# jbr_MDR1986VE1T register map
Registers are 32-bit, access not given, no defined reset value unless marked. A register's access mark holds for its fields unless they carry their own. Addresses are absolute; registers are grouped by the start of their names; [hi:lo] are bit positions; {n}, {i} and the like mark numbered series; 'fields as' and 'values as' point back to an identical list.

## TIM3
0x40080000 TIM3_CNT
0x40080004 TIM3_PSG
  [15:0] PSG
0x40080008 TIM3_ARR
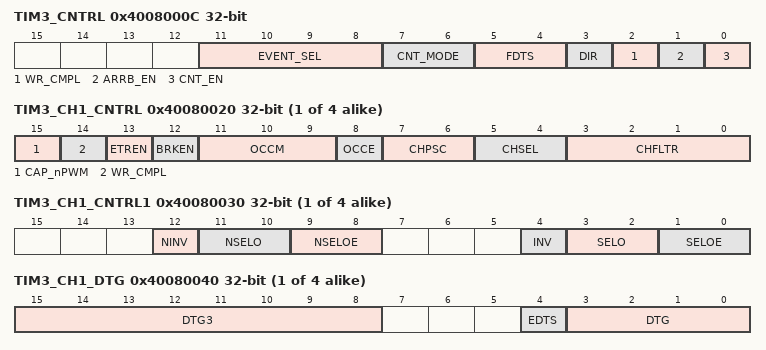
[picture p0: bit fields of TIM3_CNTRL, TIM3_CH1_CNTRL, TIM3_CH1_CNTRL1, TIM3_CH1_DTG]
0x4008000C TIM3_CNTRL
  [11:8] EVENT_SEL, [7:6] CNT_MODE, [5:4] FDTS, [3] DIR, [2] WR_CMPL, [1] ARRB_EN, [0] CNT_EN
{0x4008000C+4i} TIM3_CCR{i} (i=1..4)
  [31:0] CCR
{0x4008001C+4i} TIM3_CH{i}_CNTRL (i=1..4)
  [15] CAP_nPWM, [14] WR_CMPL, [13] ETREN, [12] BRKEN, [11:9] OCCM, [8] OCCE, [7:6] CHPSC, [5:4] CHSEL, [3:0] CHFLTR
{0x4008002C+4i} TIM3_CH{i}_CNTRL1 (i=1..4)
  [12] NINV, [11:10] NSELO, [9:8] NSELOE, [4] INV, [3:2] SELO, [1:0] SELOE
{0x4008003C+4i} TIM3_CH{i}_DTG (i=1..4)
  [15:8] DTG3, [4] EDTS, [3:0] DTG
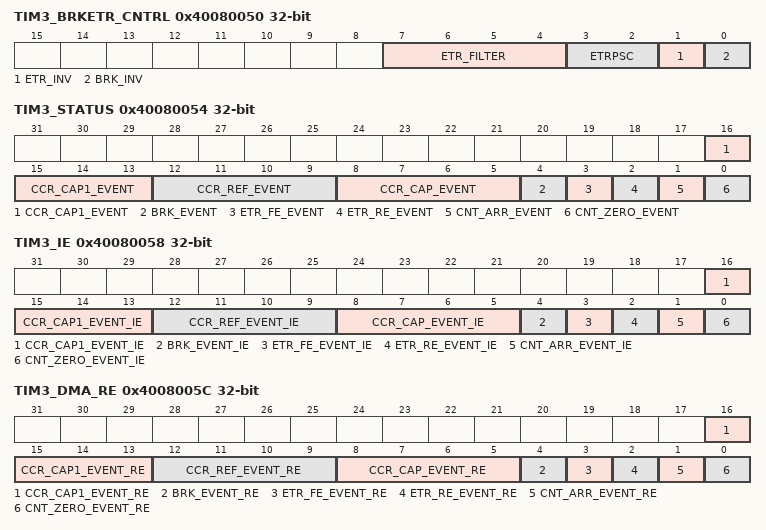
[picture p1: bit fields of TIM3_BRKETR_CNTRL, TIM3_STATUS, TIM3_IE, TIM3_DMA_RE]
0x40080050 TIM3_BRKETR_CNTRL
  [7:4] ETR_FILTER, [3:2] ETRPSC, [1] ETR_INV, [0] BRK_INV
0x40080054 TIM3_STATUS
  [16:13] CCR_CAP1_EVENT, [12:9] CCR_REF_EVENT, [8:5] CCR_CAP_EVENT, [4] BRK_EVENT, [3] ETR_FE_EVENT, [2] ETR_RE_EVENT, [1] CNT_ARR_EVENT, [0] CNT_ZERO_EVENT
0x40080058 TIM3_IE
  [16:13] CCR_CAP1_EVENT_IE, [12:9] CCR_REF_EVENT_IE, [8:5] CCR_CAP_EVENT_IE, [4] BRK_EVENT_IE, [3] ETR_FE_EVENT_IE, [2] ETR_RE_EVENT_IE, [1] CNT_ARR_EVENT_IE, [0] CNT_ZERO_EVENT_IE
0x4008005C TIM3_DMA_RE
  [16:13] CCR_CAP1_EVENT_RE, [12:9] CCR_REF_EVENT_RE, [8:5] CCR_CAP_EVENT_RE, [4] BRK_EVENT_RE, [3] ETR_FE_EVENT_RE, [2] ETR_RE_EVENT_RE, [1] CNT_ARR_EVENT_RE, [0] CNT_ZERO_EVENT_RE
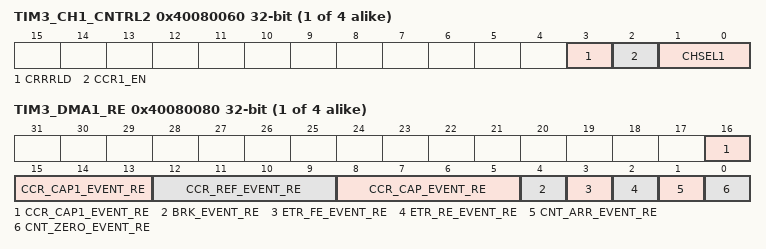
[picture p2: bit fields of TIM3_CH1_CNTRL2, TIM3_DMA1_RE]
{0x4008005C+4i} TIM3_CH{i}_CNTRL2 (i=1..4)
  [3] CRRRLD, [2] CCR1_EN, [1:0] CHSEL1
0x40080070 TIM3_CCR11
  [31:0] CCR1
0x40080074 TIM3_CCR21
  [31:0] CCR1
0x40080078 TIM3_CCR31
  [31:0] CCR1
0x4008007C TIM3_CCR41
  [31:0] CCR1
{0x4008007C+4i} TIM3_DMA{i}_RE (i=1..4)
  fields as TIM3_DMA_RE

## TIM4
0x40098000 TIM4_CNT
0x40098004 TIM4_PSG
  [15:0] PSG
0x40098008 TIM4_ARR
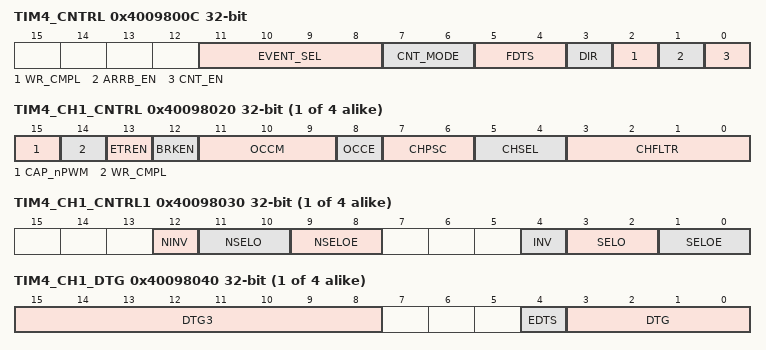
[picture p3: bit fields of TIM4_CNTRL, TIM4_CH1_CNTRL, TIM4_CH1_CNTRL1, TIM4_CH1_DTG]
0x4009800C TIM4_CNTRL
  [11:8] EVENT_SEL, [7:6] CNT_MODE, [5:4] FDTS, [3] DIR, [2] WR_CMPL, [1] ARRB_EN, [0] CNT_EN
{0x4009800C+4i} TIM4_CCR{i} (i=1..4)
  [31:0] CCR
{0x4009801C+4i} TIM4_CH{i}_CNTRL (i=1..4)
  [15] CAP_nPWM, [14] WR_CMPL, [13] ETREN, [12] BRKEN, [11:9] OCCM, [8] OCCE, [7:6] CHPSC, [5:4] CHSEL, [3:0] CHFLTR
{0x4009802C+4i} TIM4_CH{i}_CNTRL1 (i=1..4)
  [12] NINV, [11:10] NSELO, [9:8] NSELOE, [4] INV, [3:2] SELO, [1:0] SELOE
{0x4009803C+4i} TIM4_CH{i}_DTG (i=1..4)
  [15:8] DTG3, [4] EDTS, [3:0] DTG
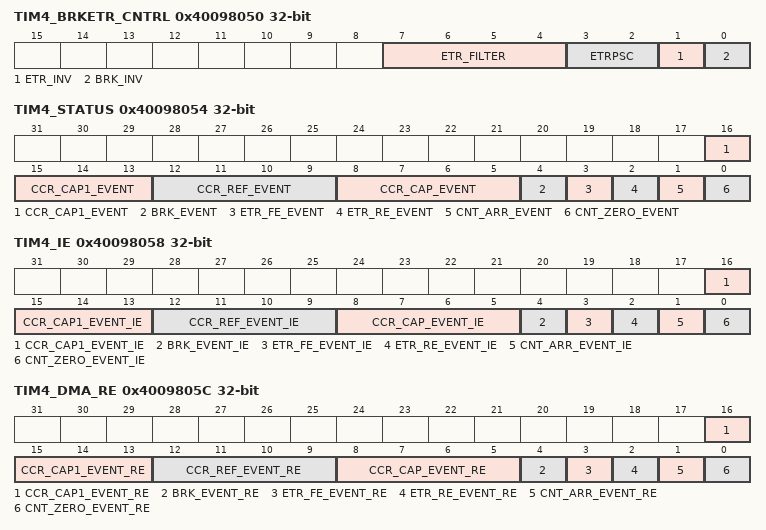
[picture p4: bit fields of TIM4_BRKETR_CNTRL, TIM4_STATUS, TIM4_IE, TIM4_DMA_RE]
0x40098050 TIM4_BRKETR_CNTRL
  [7:4] ETR_FILTER, [3:2] ETRPSC, [1] ETR_INV, [0] BRK_INV
0x40098054 TIM4_STATUS
  [16:13] CCR_CAP1_EVENT, [12:9] CCR_REF_EVENT, [8:5] CCR_CAP_EVENT, [4] BRK_EVENT, [3] ETR_FE_EVENT, [2] ETR_RE_EVENT, [1] CNT_ARR_EVENT, [0] CNT_ZERO_EVENT
0x40098058 TIM4_IE
  [16:13] CCR_CAP1_EVENT_IE, [12:9] CCR_REF_EVENT_IE, [8:5] CCR_CAP_EVENT_IE, [4] BRK_EVENT_IE, [3] ETR_FE_EVENT_IE, [2] ETR_RE_EVENT_IE, [1] CNT_ARR_EVENT_IE, [0] CNT_ZERO_EVENT_IE
0x4009805C TIM4_DMA_RE
  [16:13] CCR_CAP1_EVENT_RE, [12:9] CCR_REF_EVENT_RE, [8:5] CCR_CAP_EVENT_RE, [4] BRK_EVENT_RE, [3] ETR_FE_EVENT_RE, [2] ETR_RE_EVENT_RE, [1] CNT_ARR_EVENT_RE, [0] CNT_ZERO_EVENT_RE
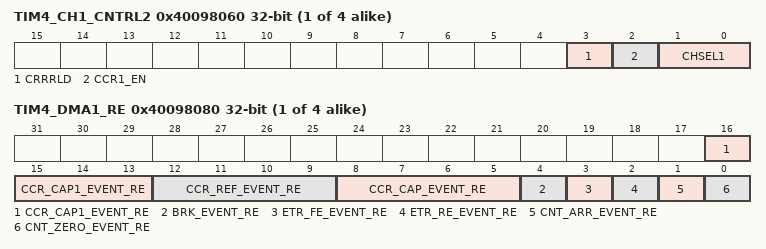
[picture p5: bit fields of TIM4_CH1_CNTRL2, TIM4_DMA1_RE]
{0x4009805C+4i} TIM4_CH{i}_CNTRL2 (i=1..4)
  [3] CRRRLD, [2] CCR1_EN, [1:0] CHSEL1
0x40098070 TIM4_CCR11
  [31:0] CCR1
0x40098074 TIM4_CCR21
  [31:0] CCR1
0x40098078 TIM4_CCR31
  [31:0] CCR1
0x4009807C TIM4_CCR41
  [31:0] CCR1
{0x4009807C+4i} TIM4_DMA{i}_RE (i=1..4)
  fields as TIM4_DMA_RE

## UART1
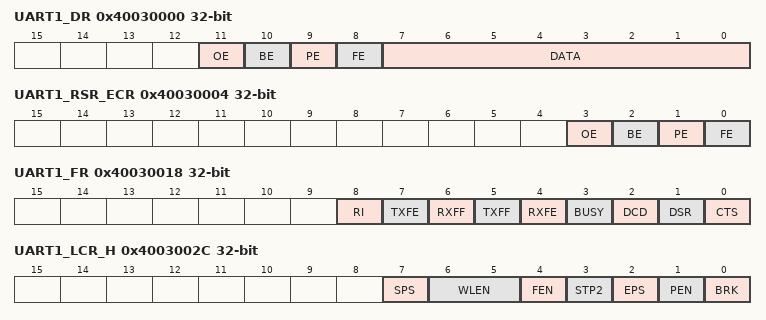
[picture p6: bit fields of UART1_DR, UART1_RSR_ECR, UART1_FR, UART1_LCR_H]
0x40030000 UART1_DR
  [11] OE, [10] BE, [9] PE, [8] FE, [7:0] DATA
0x40030004 UART1_RSR_ECR
  [3] OE, [2] BE, [1] PE, [0] FE
0x40030018 UART1_FR
  [8] RI, [7] TXFE, [6] RXFF, [5] TXFF, [4] RXFE, [3] BUSY, [2] DCD, [1] DSR, [0] CTS
0x40030020 UART1_ILPR
  [7:0] ILPDVSR
0x40030024 UART1_IBRD
  [15:0] BAUDDIV_INT
0x40030028 UART1_FBRD
  [5:0] BAUDDIV_FRAC
0x4003002C UART1_LCR_H
  [7] SPS, [6:5] WLEN, [4] FEN, [3] STP2, [2] EPS, [1] PEN, [0] BRK
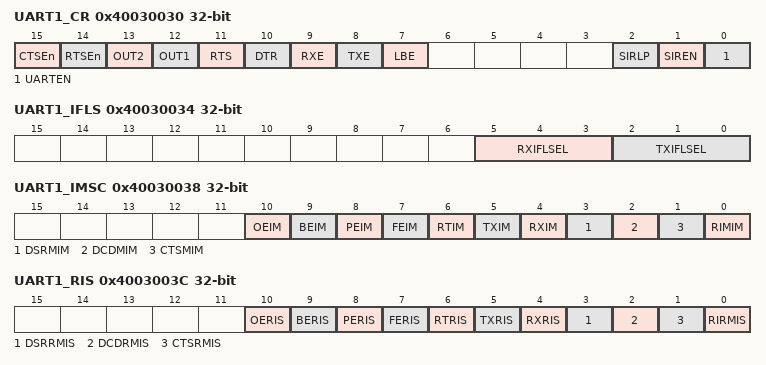
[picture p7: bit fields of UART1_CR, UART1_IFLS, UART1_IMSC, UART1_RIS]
0x40030030 UART1_CR
  [15] CTSEn, [14] RTSEn, [13] OUT2, [12] OUT1, [11] RTS, [10] DTR, [9] RXE, [8] TXE, [7] LBE, [2] SIRLP, [1] SIREN, [0] UARTEN
0x40030034 UART1_IFLS
  [5:3] RXIFLSEL, [2:0] TXIFLSEL
0x40030038 UART1_IMSC
  [10] OEIM, [9] BEIM, [8] PEIM, [7] FEIM, [6] RTIM, [5] TXIM, [4] RXIM, [3] DSRMIM, [2] DCDMIM, [1] CTSMIM, [0] RIMIM
0x4003003C UART1_RIS
  [10] OERIS, [9] BERIS, [8] PERIS, [7] FERIS, [6] RTRIS, [5] TXRIS, [4] RXRIS, [3] DSRRMIS, [2] DCDRMIS, [1] CTSRMIS, [0] RIRMIS
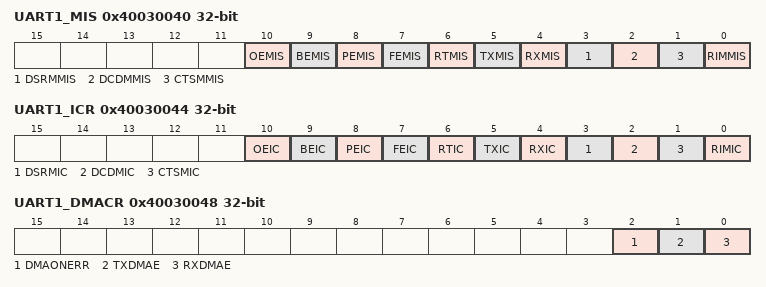
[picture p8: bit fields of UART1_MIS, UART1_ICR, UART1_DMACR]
0x40030040 UART1_MIS
  [10] OEMIS, [9] BEMIS, [8] PEMIS, [7] FEMIS, [6] RTMIS, [5] TXMIS, [4] RXMIS, [3] DSRMMIS, [2] DCDMMIS, [1] CTSMMIS, [0] RIMMIS
0x40030044 UART1_ICR
  [10] OEIC, [9] BEIC, [8] PEIC, [7] FEIC, [6] RTIC, [5] TXIC, [4] RXIC, [3] DSRMIC, [2] DCDMIC, [1] CTSMIC, [0] RIMIC
0x40030048 UART1_DMACR
  [2] DMAONERR, [1] TXDMAE, [0] RXDMAE
